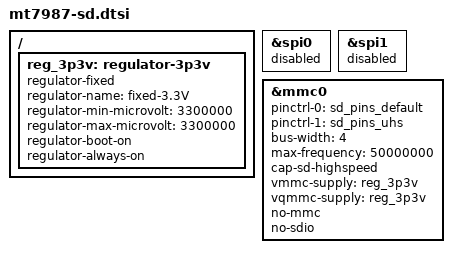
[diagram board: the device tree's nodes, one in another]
// SPDX-License-Identifier: (GPL-2.0 OR MIT)

#include "mt7987-pinctrl.dtsi"

/ {
	reg_3p3v: regulator-3p3v {
		compatible = "regulator-fixed";
		regulator-name = "fixed-3.3V";
		regulator-min-microvolt = <3300000>;
		regulator-max-microvolt = <3300000>;
		regulator-boot-on;
		regulator-always-on;
	};
};

/* Disable spi0/spi1 node since MSDC shares pins with spi0 and spi1*/
&spi0 {
	status = "disabled";
};

&spi1 {
	status = "disabled";
};

&mmc0 {
	pinctrl-names = "default", "state_uhs";
	pinctrl-0 = <&sd_pins_default>;
	pinctrl-1 = <&sd_pins_uhs>;
	bus-width = <4>;
	max-frequency = <50000000>;
	cap-sd-highspeed;
	vmmc-supply = <&reg_3p3v>;
	vqmmc-supply = <&reg_3p3v>;
	no-mmc;
	no-sdio;
	status = "okay";
};
